# CAM_CM register map
Vendor: Texas Instruments
Peripheral module from a debugger description file (folder omap34xx).
Registers are 32-bit, access per field, reset values left out (the file's numbers can be read two ways) unless marked. A register's access mark holds for its fields unless they carry their own. Offsets are as the file gives them; lines under a group give offsets from that group; [hi:lo] are bit positions; {n}, {i} and the like mark numbered series; 'fields as' and 'values as' point back to an identical list; <NAME> marks a mode.

## CAM_CM
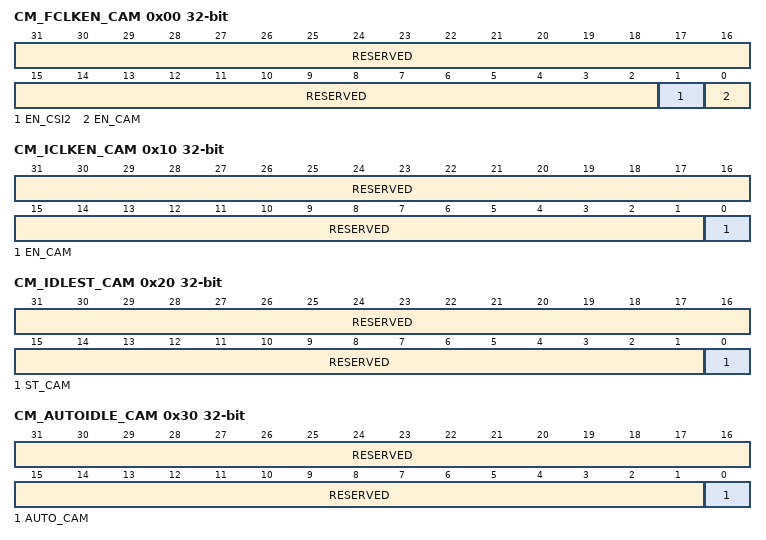
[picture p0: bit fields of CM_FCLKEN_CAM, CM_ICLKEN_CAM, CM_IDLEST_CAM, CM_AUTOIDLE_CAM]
0x00 CM_FCLKEN_CAM — Controls the modules functional clock activity.
  [31:2] RESERVED ro — Write 0s for future compatibility. Read returns 0.
  [1] EN_CSI2 rw — CSI2 functional clock control (96 MHz)
    0=CSI2_96M_FCLK is disabled; 1=CSI2_96M_FCLK is enabled
  [0] EN_CAM rw — Camera functional clock control
    0=CAM_MCLK is disabled; 1=CAM_MCLK is enabled
0x10 CM_ICLKEN_CAM — Controls the modules interface clock activity.
  [31:1] RESERVED ro — Write 0s for future compatibility. Read returns 0.
  [0] EN_CAM rw — Camera interface clock control
    0=CAM_L3_ICK and CAM_L4_ICLK are disabled; 1=CAM_L3_ICK and CAM_L4_ICLK are enabled
0x20 CM_IDLEST_CAM ro — Modules access availability monitoring. This register is read only and automatically updated.
  [31:1] RESERVED — Read returns 0.
  [0] ST_CAM — Camera standby status.
    0=Camera is active; 1=Camera is in standby mode
0x30 CM_AUTOIDLE_CAM — This register controls the automatic control of the modules interface clock activity.
  [31:1] RESERVED ro — Write 0s for future compatibility. Read returns 0.
  [0] AUTO_CAM rw — Camera auto clock control.
    0=Camera clock is unrelated to the domain state transition; 1=Camera clock is automatically enabled or disabled along with the domain state transition
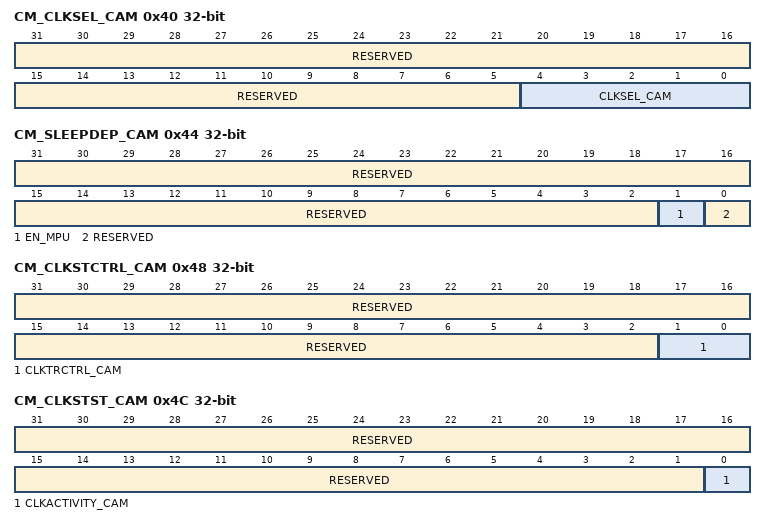
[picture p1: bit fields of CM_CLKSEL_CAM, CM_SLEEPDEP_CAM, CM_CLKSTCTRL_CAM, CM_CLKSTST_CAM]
0x40 CM_CLKSEL_CAM — CAM module clock selection.
  [31:5] RESERVED ro — Write 0s for future compatibility. Read returns 0.
  [4:0] CLKSEL_CAM rw — CAM_MCLK divider factor DPLL4 M5 (1 up to 16); Other enums: Reserved
    {v}=CAM_MCLK is DPLL4 clock divided by {v} (v=1..16)
0x44 CM_SLEEPDEP_CAM — This register allows enabling or disabling the sleep transition dependency of CAM domain with respect to other domain.
  [31:2] RESERVED ro — Write 0s for future compatibility. Read returns 0.
  [1] EN_MPU rw — MPU domain dependency
    0=CAM domain sleep dependency with MPU domain is disabled; 1=CAM domain sleep dependency with MPU domain is enabled
  [0] RESERVED ro — Write 0s for future compatibility. Read returns 0.
0x48 CM_CLKSTCTRL_CAM — This register allows to enable or disable SW and HW supervised transition between ACTIVE and INACTIVE states.
  [31:2] RESERVED ro — Write 0s for future compatibility. Read returns 0.
  [1:0] CLKTRCTRL_CAM rw — Controls the clock state transition of the CAMERA clock domain.
    0=Automatic transition is disabled; 1=Start a software supervised sleep transition on the domain; 2=Start a software supervised wake-up transition on the domain; 3=Automatic transition is enabled. Transition is supervised by the hardware.
0x4C CM_CLKSTST_CAM ro — This register provides a status on the OCP interface clock activity in the domain.
  [31:1] RESERVED — Write 0s for future compatibility. Read returns 0.
  [0] CLKACTIVITY_CAM — Interface clock activity status
    0=No domain interface clock activity; 1=Domain interface clock is active
